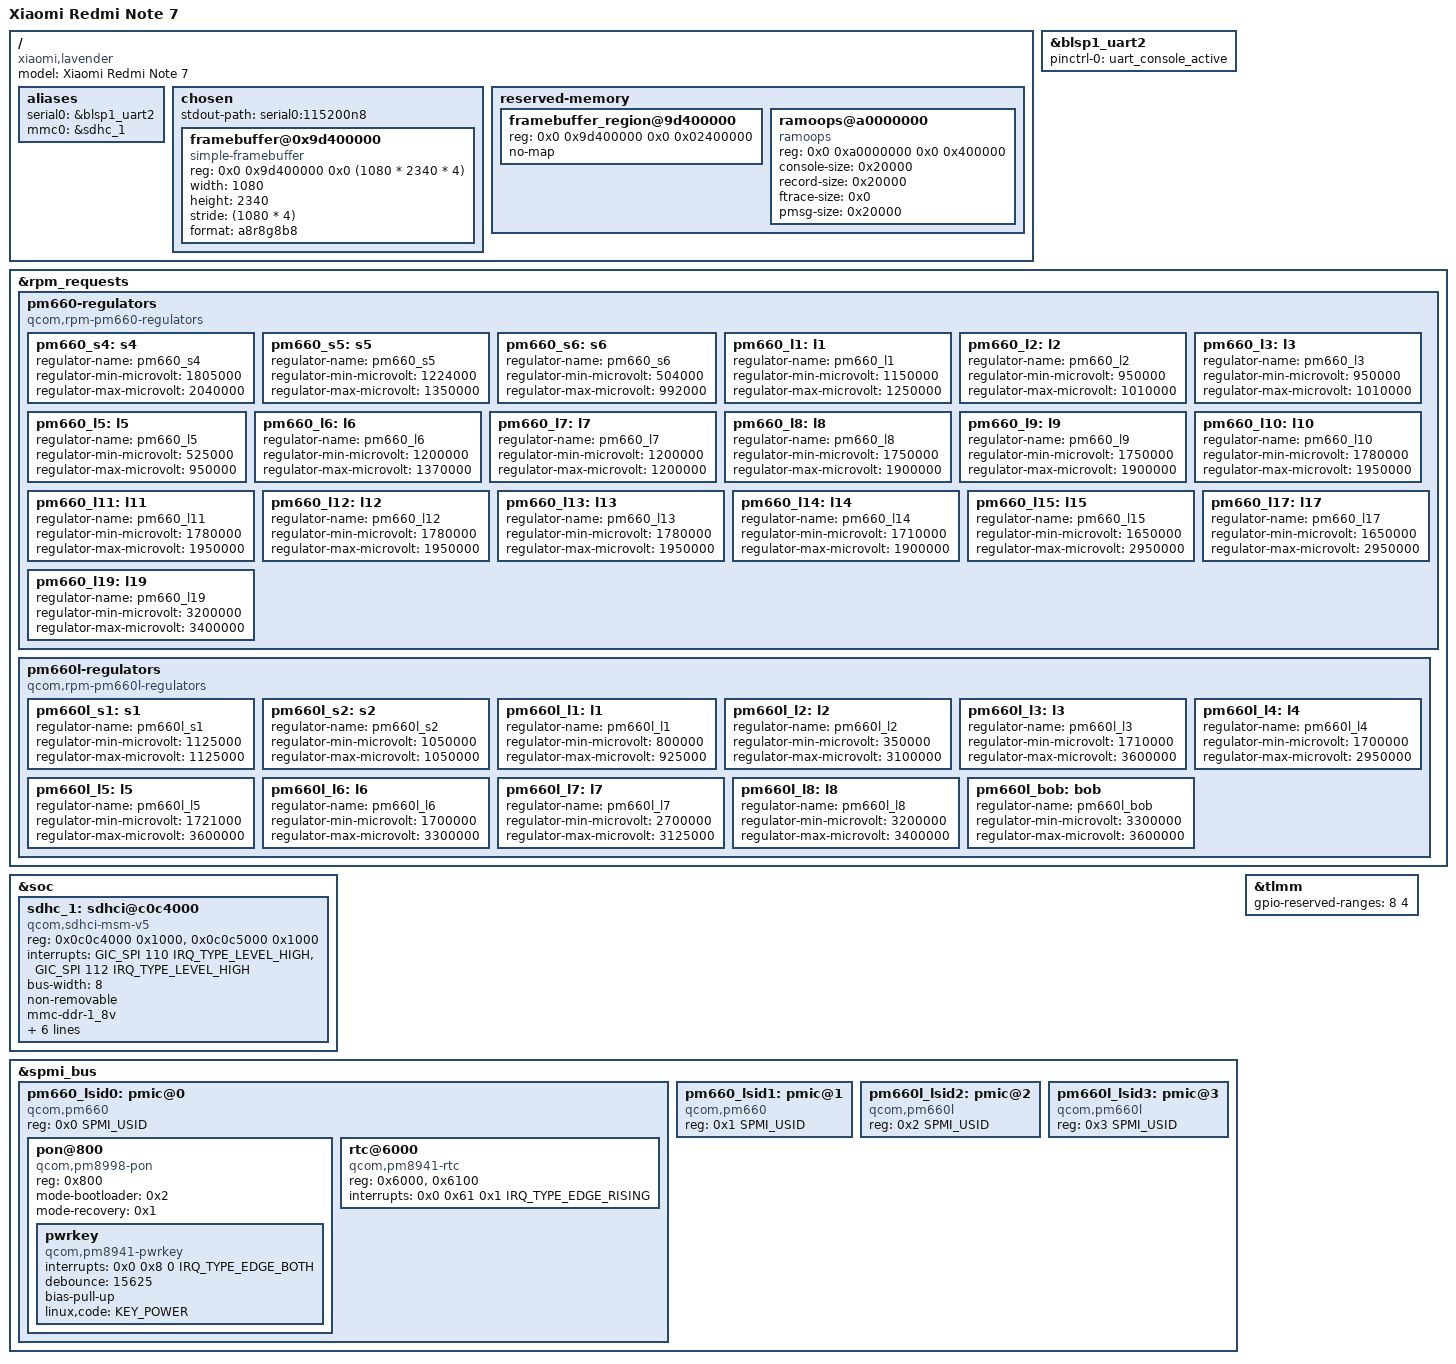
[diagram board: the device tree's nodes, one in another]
// SPDX-License-Identifier: GPL-2.0-only
/*
 * Copyright (c) 2020, Alexey Minnekhanov <alexey.min@gmail.com>
 */

/dts-v1/;

#include "sdm660.dtsi"
#include <dt-bindings/spmi/spmi.h>
#include <dt-bindings/input/linux-event-codes.h>

/ {
	model = "Xiaomi Redmi Note 7";
	compatible = "xiaomi,lavender", "qcom,sdm660";

	aliases {
		serial0 = &blsp1_uart2;
		mmc0 = &sdhc_1;
	};

	chosen {
		#address-cells = <2>;
		#size-cells = <2>;
		ranges;

		stdout-path = "serial0:115200n8";

		framebuffer@0x9d400000 {
			compatible = "simple-framebuffer";
			reg = <0x0 0x9d400000 0x0 (1080 * 2340 * 4)>;
			width = <1080>;
			height = <2340>;
			stride = <(1080 * 4)>;
			format = "a8r8g8b8";
		};

	};

	reserved-memory {
		#address-cells = <2>;
		#size-cells = <2>;
		ranges;

		framebuffer_region@9d400000 {
			reg = <0x0 0x9d400000 0x0 0x02400000>;
			no-map;
		};


		ramoops@a0000000 {
			compatible = "ramoops";
			reg = <0x0 0xa0000000 0x0 0x400000>;
			console-size = <0x20000>;
			record-size = <0x20000>;
			ftrace-size = <0x0>;
			pmsg-size = <0x20000>;
		};
	};
};

&blsp1_uart2 {
	status = "okay";
	pinctrl-names = "default";
	pinctrl-0 = <&uart_console_active>;
};

&rpm_requests {
	pm660-regulators {
		status = "okay";
		compatible = "qcom,rpm-pm660-regulators";

		pm660_s4: s4 {
			regulator-name = "pm660_s4";
			regulator-min-microvolt = <1805000>;
			regulator-max-microvolt = <2040000>;
		};
		pm660_s5: s5 {
			regulator-name = "pm660_s5";
			regulator-min-microvolt = <1224000>;
			regulator-max-microvolt = <1350000>;
		};
		pm660_s6: s6 {
			regulator-name = "pm660_s6";
			regulator-min-microvolt = <504000>;
			regulator-max-microvolt = <992000>;
		};
		pm660_l1: l1 {
			regulator-name = "pm660_l1";
			regulator-min-microvolt = <1150000>;
			regulator-max-microvolt = <1250000>;
		};
		pm660_l2: l2 {
			regulator-name = "pm660_l2";
			regulator-min-microvolt = <950000>;
			regulator-max-microvolt = <1010000>;
		};
		pm660_l3: l3 {
			regulator-name = "pm660_l3";
			regulator-min-microvolt = <950000>;
			regulator-max-microvolt = <1010000>;
		};
		pm660_l5: l5 {
			regulator-name = "pm660_l5";
			regulator-min-microvolt = <525000>;
			regulator-max-microvolt = <950000>;
		};
		pm660_l6: l6 {
			regulator-name = "pm660_l6";
			regulator-min-microvolt = <1200000>;
			regulator-max-microvolt = <1370000>;
		};
		pm660_l7: l7 {
			regulator-name = "pm660_l7";
			regulator-min-microvolt = <1200000>;
			regulator-max-microvolt = <1200000>;
		};
		pm660_l8: l8 {
			regulator-name = "pm660_l8";
			regulator-min-microvolt = <1750000>;
			regulator-max-microvolt = <1900000>;
			//regulator-allow-set-load;
			//regulator-system-load = <200000>;
		};
		pm660_l9: l9 {
			regulator-name = "pm660_l9";
			regulator-min-microvolt = <1750000>;
			regulator-max-microvolt = <1900000>;
		};
		pm660_l10: l10 {
			regulator-name = "pm660_l10";
			regulator-min-microvolt = <1780000>;
			regulator-max-microvolt = <1950000>;
		};
		pm660_l11: l11 {
			regulator-name = "pm660_l11";
			regulator-min-microvolt = <1780000>;
			regulator-max-microvolt = <1950000>;
		};
		pm660_l12: l12 {
			regulator-name = "pm660_l12";
			regulator-min-microvolt = <1780000>;
			regulator-max-microvolt = <1950000>;
		};
		pm660_l13: l13 {
			regulator-name = "pm660_l13";
			regulator-min-microvolt = <1780000>;
			regulator-max-microvolt = <1950000>;
		};
		pm660_l14: l14 {
			regulator-name = "pm660_l14";
			regulator-min-microvolt = <1710000>;
			regulator-max-microvolt = <1900000>;
		};
		pm660_l15: l15 {
			regulator-name = "pm660_l15";
			regulator-min-microvolt = <1650000>;
			regulator-max-microvolt = <2950000>;
		};
		pm660_l17: l17 {
			regulator-name = "pm660_l17";
			regulator-min-microvolt = <1650000>;
			regulator-max-microvolt = <2950000>;
		};
		pm660_l19: l19 {
			regulator-name = "pm660_l19";
			regulator-min-microvolt = <3200000>;
			regulator-max-microvolt = <3400000>;
		};
	};

	pm660l-regulators {
		status = "okay";
		compatible = "qcom,rpm-pm660l-regulators";

		//vdd_l4_l6-supply = <&pm660l_bob>; // in schematics, but unsure
		/* downstream has this in dmesg: pm660l_l7: supplied by pm660_l10 */

		pm660l_s1: s1 {
			regulator-name = "pm660l_s1";
			regulator-min-microvolt = <1125000>;
			regulator-max-microvolt = <1125000>;
		};
		pm660l_s2: s2 {
			regulator-name = "pm660l_s2";
			regulator-min-microvolt = <1050000>;
			regulator-max-microvolt = <1050000>;
		};
		pm660l_l1: l1 {
			regulator-name = "pm660l_l1";
			regulator-min-microvolt = <800000>;
			regulator-max-microvolt = <925000>;
		};
		pm660l_l2: l2 {
			regulator-name = "pm660l_l2";
			regulator-min-microvolt = <350000>;
			regulator-max-microvolt = <3100000>;
		};
		pm660l_l3: l3 {
			regulator-name = "pm660l_l3";
			regulator-min-microvolt = <1710000>;
			regulator-max-microvolt = <3600000>;
		};
		pm660l_l4: l4 {
			regulator-name = "pm660l_l4";
			regulator-min-microvolt = <1700000>;
			regulator-max-microvolt = <2950000>;
			//regulator-allow-set-load;
			//regulator-system-load = <200000>;
		};
		pm660l_l5: l5 {
			regulator-name = "pm660l_l5";
			regulator-min-microvolt = <1721000>;
			regulator-max-microvolt = <3600000>;
		};
		pm660l_l6: l6 {
			regulator-name = "pm660l_l6";
			regulator-min-microvolt = <1700000>;
			regulator-max-microvolt = <3300000>;
		};
		pm660l_l7: l7 {
			regulator-name = "pm660l_l7";
			regulator-min-microvolt = <2700000>;
			regulator-max-microvolt = <3125000>;
		};
		pm660l_l8: l8 {
			regulator-name = "pm660l_l8";
			regulator-min-microvolt = <3200000>;
			regulator-max-microvolt = <3400000>;
		};
		pm660l_bob: bob {
			regulator-name = "pm660l_bob";
			regulator-min-microvolt = <3300000>;
			regulator-max-microvolt = <3600000>;
		};
	};
};

&soc {
/*
[    2.484654] sdhci_msm c0c4000.sdhci: No vmmc regulator found
[    2.484669] sdhci_msm c0c4000.sdhci: No vqmmc regulator found
[    2.485147] mmc0: SDHCI controller on c0c4000.sdhci [c0c4000.sdhci] using 64-bit ADMA in CMDQ mode
[    2.552072] mmc0: Out-of-interrupt timeout is 100[ms]
[    2.552091] mmc0: eMMC FW version: 0x02
[    2.552103] mmc0: CMDQ supported: depth: 16
[    2.552116] mmc0: cache barrier support 0 flush policy 0
[    2.557381] cmdq_host_alloc_tdl: desc_size: 1024 data_sz: 63488 slot-sz: 32
[    2.557615] mmc0: CMDQ enabled on card
[    2.557636] mmc0: new HS400 Enhanced strobe MMC card at address 0001
*/
	sdhc_1: sdhci@c0c4000 {
		compatible = "qcom,sdhci-msm-v5";
		status = "okay";
		reg = <0x0c0c4000 0x1000>,
		      <0x0c0c5000 0x1000>;
		/* reg-names = "hc", "core"; // SD Core register map is required for controllers earlier than msm-v5 */
		reg-names = "hc", "cqhci";  /* downstream log says cmdq is supported */
		/* ^^ downstream has those as: "hc_mem", "cmdq_mem"; */

		interrupts = <GIC_SPI 110 IRQ_TYPE_LEVEL_HIGH>,
			     <GIC_SPI 112 IRQ_TYPE_LEVEL_HIGH>;
		interrupt-names = "hc_irq", "pwr_irq";

		bus-width = <8>;
		non-removable;
		mmc-ddr-1_8v;    /* eMMC high-speed DDR mode (1.8V I/O) is supported. */
		mmc-hs200-1_8v;  /* eMMC HS200 mode (1.8V I/O) is supported. */
		mmc-hs400-1_8v;  /* eMMC HS400 mode (1.8V I/O) is supported. */

		/* downstream has those specified, but its dmesg says supplies not found? disable for now */
		/* vmmc-supply = <&pm660l_l4>;  // Supply for the card power */
		/* vqmmc-supply = <&pm660_l8>;  // Supply for the bus IO line power */
		/* ^^ uncommenting any of those supplies (especially vqmmc)
		 *    makes device reboot during probe */

		pinctrl-names = "default";
		pinctrl-0 = <&sdc1_clk &sdc1_cmd &sdc1_data &sdc1_rclk>;

		clocks = <&gcc GCC_SDCC1_APPS_CLK>,
			 <&gcc GCC_SDCC1_AHB_CLK>;
		clock-names = "core", "iface";

		/* some downstream data:
		qcom,bus-speed-mode = "HS400_1p8v", "HS200_1p8v", "DDR_1p8v";
		qcom,scaling-lower-bus-speed-mode = "DDR52";
		^^ those in mainline probably are mmc-ddr*, mmc-hs200*, mmc-hs400* props
		*/
	};
};

&spmi_bus {
	pm660_lsid0: pmic@0 {
		compatible = "qcom,pm660", "qcom,spmi-pmic";
		reg = <0x0 SPMI_USID>;
		#address-cells = <0x1>;
		#size-cells = <0x0>;

		pon@800 {
			compatible = "qcom,pm8998-pon";
			reg = <0x800>;
			mode-bootloader = <0x2>;
			mode-recovery = <0x1>;

			pwrkey {
				compatible = "qcom,pm8941-pwrkey";
				interrupts = <0x0 0x8 0 IRQ_TYPE_EDGE_BOTH>;
				debounce = <15625>;
				bias-pull-up;
				linux,code = <KEY_POWER>;
			};
		};

		rtc@6000 {
			compatible = "qcom,pm8941-rtc";
			reg = <0x6000>, <0x6100>;
			reg-names = "rtc", "alarm";
			interrupts = <0x0 0x61 0x1 IRQ_TYPE_EDGE_RISING>;
		};
		
		/* also: temp alarm, gpios, coincell, vadc, charger, pdphy, rradc, fuelgauge */
	};

	pm660_lsid1: pmic@1 {
		compatible = "qcom,pm660", "qcom,spmi-pmic";
		reg = <0x1 SPMI_USID>;
		#address-cells = <0x1>;
		#size-cells = <0x0>;

		/* haptic node */
	};

	pm660l_lsid2: pmic@2 {
		compatible = "qcom,pm660l", "qcom,spmi-pmic";
		reg = <0x2 SPMI_USID>;
		#address-cells = <1>;
		#size-cells = <0>;

		/* tz temp alarm */
	};

	pm660l_lsid3: pmic@3 {
		compatible = "qcom,pm660l", "qcom,spmi-pmic";
		reg = <0x3 SPMI_USID>;
		#address-cells = <1>;
		#size-cells = <0>;

		/* pwms, leds, flash, torch */
	};
};

&tlmm {
	gpio-reserved-ranges = <8 4>;
};
